# EFR32BG22C222F352GM40 register map
Vendor: Silicon Labs; Series: EFR32; File version: C
Registers are 32-bit, read-write, reset 0x0 unless marked. A register's access mark holds for its fields unless they carry their own. Offsets are from the block's base; [hi:lo] are bit positions; {n}, {i} and the like mark numbered series.

## SYSCFG_S — SYSCFG_S Registers
Base 0x4007C000
Same registers: SYSCFG_NS 0x5007C000
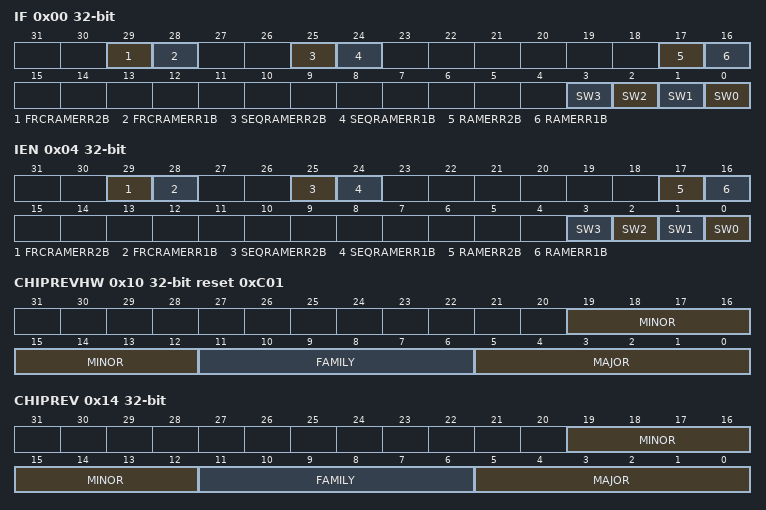
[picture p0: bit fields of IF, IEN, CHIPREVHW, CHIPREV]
0x00 IF — Read to get system status.
  [29] FRCRAMERR2B — FRCRAM 2-Bit Error Interrupt Flag
  [28] FRCRAMERR1B — FRCRAM 1-Bit Error Interrupt Flag
  [25] SEQRAMERR2B — SEQRAM 2-Bit Error Interrupt Flag
  [24] SEQRAMERR1B — SEQRAM 1-Bit Error Interrupt Flag
  [17] RAMERR2B — RAM 2-Bit Error Interrupt Flag
  [16] RAMERR1B — RAM 1-Bit Error Interrupt Flag
  [n] SW{n} (n=0..3) — Software Interrupt {n}
0x04 IEN — Write to enable interrupts.
  [29] FRCRAMERR2B — FRCRAM 2-bit Error Interrupt Enable
  [28] FRCRAMERR1B — FRCRAM 1-bit Error Interrupt Enable
  [25] SEQRAMERR2B — SEQRAM 2-bit Error Interrupt Enable
  [24] SEQRAMERR1B — SEQRAM 1-bit Error Interrupt Enable
  [17] RAMERR2B — RAM 2-bit Error Interrupt Enable
  [16] RAMERR1B — RAM 1-bit Error Interrupt Enable
  [n] SW{n} (n=0..3) — Software interrupt {n}
0x10 CHIPREVHW reset 0xC01 — Read to get the hard-wired chip revision.
  [19:12] MINOR — Hardwired Chip Revision Minor value
  [11:6] FAMILY — Hardwired Chip Family value
  [5:0] MAJOR — Hardwired Chip Revision Major value
0x14 CHIPREV — Read to get the chip revision programmed by feature configuration.
  [19:12] MINOR — Chip Revision Minor value
  [11:6] FAMILY — Chip Family value
  [5:0] MAJOR — Chip Revision Major value
0x20 CFGSYSTIC — Configure the source of the system tick for the M33.
  [0] SYSTICEXTCLKEN — SysTick External Clock Enable
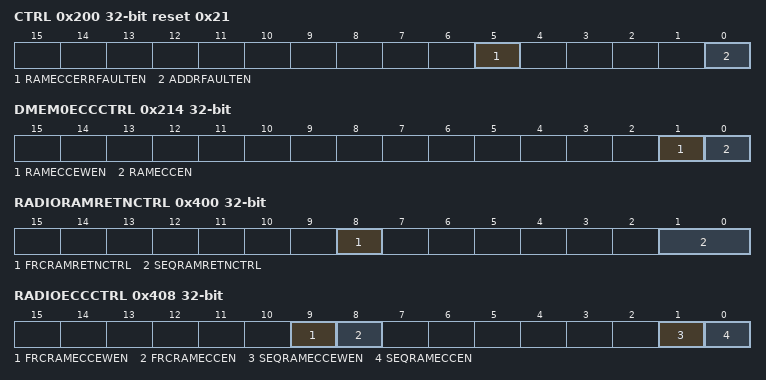
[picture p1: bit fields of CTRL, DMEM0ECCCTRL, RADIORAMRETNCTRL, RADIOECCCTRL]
0x200 CTRL reset 0x21 — Configure to provide general RAM configuration.
  [5] RAMECCERRFAULTEN — Two bit ECC Error Bus Fault Response Enable
  [0] ADDRFAULTEN — Invalid Address Bus Fault Response Enable
0x208 DMEM0RETNCTRL — Configure to provide general RAM retention configuration.
  [1:0] RAMRETNCTRL — DMEM0 blockset retention control
    0=ALLON (None of the RAM blocks powered down); 1=BLK0 (Power down RAM block 0); 2=BLK1 (Power down RAM block 1)
0x210 DMEM0ECCADDR ro — Read to get status of the DMEM0 ECC error address.
  [31:0] DMEM0ECCADDR — DMEM0 RAM ECC Error Address
0x214 DMEM0ECCCTRL — Configure to set RAM ECC control.
  [1] RAMECCEWEN — RAM ECC Error Writeback Enable
  [0] RAMECCEN — RAM ECC Enable
0x400 RADIORAMRETNCTRL — Configure SEQRAM Retention controls.
  [8] FRCRAMRETNCTRL — FRCRAM Retention Control
    0=ALLON (FRCRAM not powered down); 1=ALLOFF (Power down FRCRAM)
  [1:0] SEQRAMRETNCTRL — SEQRAM Retention Control
    0=ALLON (SEQRAM not powered down); 1=BLK0 (Power down SEQRAM block 0); 2=BLK1 (Power down SEQRAM block 1); 3=ALLOFF (Power down all SEQRAM blocks)
0x408 RADIOECCCTRL — Configure to set RAM ECC control.
  [9] FRCRAMECCEWEN — FRCRAM ECC Error Writeback Enable
  [8] FRCRAMECCEN — FRCRAM ECC Enable
  [1] SEQRAMECCEWEN — SEQRAM ECC Error Writeback Enable
  [0] SEQRAMECCEN — SEQRAM ECC Enable
0x410 SEQRAMECCADDR ro — Read to get status of the SEQRAM ECC error address.
  [31:0] SEQRAMECCADDR — SEQRAM ECC Address
0x414 FRCRAMECCADDR ro — Read to get status of the FRCRAM ECC error address.
  [31:0] FRCRAMECCADDR — FRCRAM ECC Error Address
0x600 ROOTDATA0 — Data in this register is passed to the trusted root firmware upon reset.
  [31:0] DATA
0x604 ROOTDATA1 — Data in this register is passed to the trusted root firmware upon reset.
  [31:0] DATA
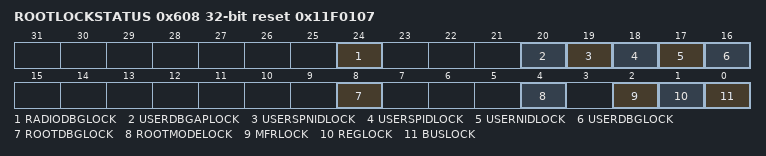
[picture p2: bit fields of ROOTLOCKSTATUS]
0x608 ROOTLOCKSTATUS ro reset 0x11F0107 — This register returns the status of the SE managed locks.
  [24] RADIODBGLOCK — Radio Debug Lock
  [20] USERDBGAPLOCK — User Debug Access Port Lock
  [19] USERSPNIDLOCK — User Secure Non-invasive Debug Lock
  [18] USERSPIDLOCK — User Secure Invasive Debug Lock
  [17] USERNIDLOCK — User Non-invasive Debug Lock
  [16] USERDBGLOCK — User Invasive Debug Lock
  [8] ROOTDBGLOCK — Root Debug Lock
  [4] ROOTMODELOCK
  [2] MFRLOCK — Manufacture Lock
  [1] REGLOCK — Register Lock
  [0] BUSLOCK
